# M2354 register map
File version: 1.0
Registers are 32-bit, read-write, reset 0x0 unless marked. A register's access mark holds for its fields unless they carry their own. Offsets are from the block's base; [hi:lo] are bit positions.

## TMR5 — TIMER Register Map
Base 0x40052100
Same registers: TMR5_NS 0x50052100
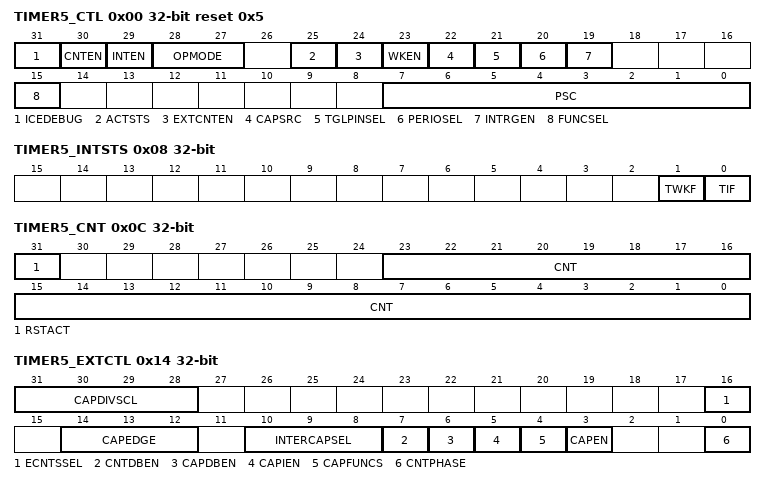
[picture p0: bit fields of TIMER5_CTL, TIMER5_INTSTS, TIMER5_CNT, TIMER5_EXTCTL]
0x00 TIMER5_CTL reset 0x5 — Timer5 Control Register
  [31] ICEDEBUG — ICE Debug Mode Acknowledge Disable Bit (Write Protect). TIMER counter will keep going no matter CPU is held by ICE or not. Note: This bit is write protected. Refer to the SYS_REGLCTL register.
    0=ICE debug mode acknowledgement effects TIMER counting; 1=ICE debug mode acknowledgement Disabled
  [30] CNTEN — Timer Counting Enable Bit. Note 3: Set enable/disable this bit needs 2 * TMR_CLK period to become active, user can read ACTSTS (TIMERx_CTL[25]) to check enable/disable command is completed or not.
    0=Stops/Suspends counting; 1=Starts counting
  [29] INTEN — Timer Interrupt Enable Bit. Note: If this bit is enabled, when the timer time-out interrupt flag TIF is set to 1, the timer interrupt signal is generated and inform to CPU.
    0=Timer time-out interrupt Disabled; 1=Timer time-out interrupt Enabled
  [28:27] OPMODE — Timer Counting Mode Select
    0=The timer controller is operated in One-shot mode; 1=The timer controller is operated in Periodic mode; 2=The timer controller is operated in Toggle-output mode; 3=The timer controller is operated in Continuous Counting mode
  [25] ACTSTS ro — Timer Active Status Bit (Read Only). This bit indicates the 24-bit up counter status. Note: This bit may active when CNT 0 transition to CNT 1.
    0=24-bit up counter is not active; 1=24-bit up counter is active
  [24] EXTCNTEN — Event Counter Mode Enable Bit. This bit is for external counting pin function enabled. Note: When timer is used as an event counter, this bit should be set to 1 and select PCLK as timer clock source.
    0=Event counter mode Disabled; 1=Event counter mode Enabled
  [23] WKEN — Wake-up Function Enable Bit. If this bit is set to 1, while timer interrupt flag TIF (TIMERx_INTSTS[0]) is 1 and INTEN (TIMERx_CTL[29]) is enabled, the timer interrupt signal will generate a wake-up trigger event to CPU.
    0=Wake-up function Disabled if timer interrupt signal generated; 1=Wake-up function Enabled if timer interrupt signal generated
  [22] CAPSRC — Capture Pin Source Selection. Note 2: MIRC clock source is only available in Timer4 ~ Timer5.
    0=Capture Function source is from TMx_EXT (x= 0~5) pin; 1=Capture Function source is from internal ACMP output signal, internal clock source (HIRC, LIRC, MIRC) or external clock (HXT, LXT)
  [21] TGLPINSEL — Toggle-output Pin Select
    0=Toggle mode output to TMx (Timer Event Counter Pin); 1=Toggle mode output to TMx_EXT (Timer External Capture Pin)
  [20] PERIOSEL — Periodic Mode Behavior Selection Enable Bit. If updated CMPDAT value CNT, CNT will be reset to default value.
    0=The behavior selection in periodic mode is Disabled; 1=The behavior selection in periodic mode is Enabled
  [19] INTRGEN — Inter-timer Trigger Mode Enable Bit. Setting this bit will enable the inter-timer trigger capture function. The Timer0/2/4 will be in event counter mode and counting with external clock source or event.Also, Timer1/3/5 will be in trigger-counting mode of capture function. Note: For Timer1/3/5, this bit is ignored and the read back value is always 0.
    0=Inter-Timer Trigger Capture mode Disabled; 1=Inter-Timer Trigger Capture mode Enabled
  [15] FUNCSEL — Function Selection. This bit sets the operation mode of Timer4 and Timer5 to PWM function.
    0=Timer controller is used as timer function; 1=Timer controller is used as PWM function
  [7:0] PSC — Prescale Counter. Note: Update prescale counter value will reset internal 8-bit prescale counter and 24-bit up counter value.
0x04 TIMER5_CMP — Timer5 Comparator Register
  [23:0] CMPDAT — Timer Comparator Value. CMPDAT is a 24-bit compared value register. When the internal 24-bit up counter value is equal to CMPDAT value, the TIF (TIMERx_INTSTS[0] Timer Interrupt Flag) will be set to 1. Note 1: Never write 0x0 or 0x1 in CMPDAT field, or the core will run into unknown state. Note 2: When timer is operating in continuous counting mode, the 24-bit up counter will keep counting continuously even if user writes a new value into CMPDAT field. But if timer is operating at other modes, the 24-bit up counter will restart counting from 0 and use the newest CMPDAT value to be the timer compared value while user writes a new value into the CMPDAT field.
0x08 TIMER5_INTSTS — Timer5 Interrupt Status Register
  [1] TWKF — Timer Wake-up Flag. This bit indicates the interrupt wake-up flag status of timer. Note: This bit is cleared by writing 1 to it.
    0=Timer does not cause CPU wake-up; 1=CPU wake-up from Idle or Power-down mode if timer time-out interrupt signal generated
  [0] TIF — Timer Interrupt Flag. This bit indicates the interrupt flag status of Timer while 24-bit timer up counter CNT (TIMERx_CNT[23:0]) value reaches to CMPDAT (TIMERx_CMP[23:0]) value. Note: This bit is cleared by writing 1 to it.
    0=No effect; 1=CNT value matches the CMPDAT value
0x0C TIMER5_CNT — Timer5 Data Register
  [31] RSTACT ro — Timer Data Register Reset Active (Read Only). This bit indicates if the counter reset operation active. When user writes this CNT register, timer starts to reset its internal 24-bit timer up-counter to 0 and reload 8-bit pre-scale counter. At the same time, timer set this flag to 1 to indicate the counter reset operation is in progress. Once the counter reset operation done, timer clear this bit to 0 automatically.
    0=Reset operation is done; 1=Reset operation triggered by writing TIMERx_CNT is in progress
  [23:0] CNT — Timer Data Register. Read operation. Read this register to get CNT value. For example: If EXTCNTEN (TIMERx_CTL[24]) is 0, user can read CNT value for getting current 24-bit counter value. If EXTCNTEN (TIMERx_CTL[24]) is 1, user can read CNT value for getting current 24-bit event input counter value. Write operation. Writing any value to this register will reset current CNT value to 0 and reload internal 8-bit prescale counter.
0x10 TIMER5_CAP ro — Timer5 Capture Data Register
  [23:0] CAPDAT — Timer Capture Data Register. When CAPEN (TIMERx_EXTCTL[3]) bit is set, the transition on the capture source matches the CAPEDGE (TIMERx_EXTCTL[14:12]) setting, CAPIF (TIMERx_EINTSTS[0]) will be set to 1 and the current timer counter value CNT (TIMERx_CNT[23:0]) will be auto-loaded into this CAPDAT field.
0x14 TIMER5_EXTCTL — Timer5 External Control Register
  [31:28] CAPDIVSCL — Timer Capture Source Divider Scale. These bits indicate the divide scale for capture source divider. Note: Sets INTERCAPSEL (TIMERx_EXTCTL[10:8]) and CAPSRC (TIMERx_CTL[22]) to select capture source.
    0=Capture source/1; 1=Capture source/2; 2=Capture source/4; 3=Capture source/8; 4=Capture source/16; 5=Capture source/32; 6=Capture source/64; 7=Capture source/128; 8=Capture source/256
  [16] ECNTSSEL — Event Counter Source Selection to Trigger Event Counter Function
    0=Event Counter input source is from TMx (x= 0~5) pin; 1=Event Counter input source is from USB internal SOF output signal
  [14:12] CAPEDGE — Timer Capture Edge Detect. When the first capture event is generated, the CNT (TIMERx_CNT[23:0]) will be reset to 0 and first CAPDAT (TIMERx_CAP[23:0]) should be to 0. Note: Set CAPSRC (TIMERx_CTL[22]) and INTERCAPSEL (TIMERx_EXTCTL[10:8]) to select capture source.
    0=Capture event occurred when detect falling edge transfer on capture source; 1=Capture event occurred when detect rising edge transfer on capture source; 2=Capture event occurred when detect both falling and rising edge transfer on capture source, and the first capture event occurred at falling edge transfer; 3=Capture event occurred when detect both rising and falling edge transfer on capture source, and the first capture event occurred at rising edge transfer; 6=First capture event occurred at falling edge, follows capture events are at rising edge transfer on capture source; 7=First capture event occurred at rising edge, follows capture events are at falling edge transfer on capture source
  [10:8] INTERCAPSEL — Internal Capture Source Select. Note: These bits only available when CAPSRC (TIMERx_CTL[22]) is 1.
    0=Capture Function source is from internal ACMP0 output signal; 1=Capture Function source is from internal ACMP1 output signal; 2=Capture Function source is from HXT; 3=Capture Function source is from LXT; 4=Capture Function source is from HIRC; 5=Capture Function source is from LIRC; 6=Capture Function source is from MIRC, only available in Timer4 and Timer5
  [7] CNTDBEN — Timer External Counter Pin De-bounce Enable Bit. Note: If this bit is enabled, the edge detection of TMx pin is detected with de-bounce circuit.
    0=TMx (x= 0~5) pin de-bounce Disabled; 1=TMx (x= 0~5) pin de-bounce Enabled
  [6] CAPDBEN — Timer Capture De-bounce Enable Bit. Note: If this bit is enabled, the edge detection of TMx_EXT pin or ACMP output is detected with de-bounce circuit.
    0=TMx_EXT (x= 0~5) pin de-bounce or ACMP output de-bounce Disabled; 1=TMx_EXT (x= 0~5) pin de-bounce or ACMP output de-bounce Enabled
  [5] CAPIEN — Timer Capture Interrupt Enable Bit
    0=TMx_EXT (x= 0~5) pin, ACMP, internal clock, or external clock detection Interrupt Disabled; 1=TMx_EXT (x= 0~5) pin, ACMP, internal clock, or external clock detection Interrupt Enabled
  [4] CAPFUNCS — Capture Function Selection. Note 1: When CAPFUNCS is 0 and CAPIF becomes 1, the current 24-bit timer counter value (CNT value) will be saved to CAPDAT field. Note 2: When CAPFUNCS is 1 and CAPIF becomes 1, the current 24-bit timer counter value (CNT value) will be saved to CAPDAT field then CNT value will be reset immediately.
    0=Capture Mode Enabled; 1=Reset Mode Enabled
  [3] CAPEN — Timer Capture Function Enable Bit. This bit enables the capture input function.
    0=Timer capture function Disabled; 1=Timer capture function Enabled
  [0] CNTPHASE — Timer External Count Phase
    0=A falling edge of external counting pin will be counted; 1=A rising edge of external counting pin will be counted
0x18 TIMER5_EINTSTS — Timer5 External Interrupt Status Register
  [0] CAPIF — Timer Capture Interrupt Flag. This bit indicates the timer capture interrupt flag status. Note 1: This bit is cleared by writing 1 to it. Note 2: When the CAPEN (TIMERx_EXTCTL[3]) bit is set, the transition on the capture source matches the CAPEDGE (TIMERx_EXTCTL[14:12]) setting, this bit will be set to 1 by hardware. Note 3: There is a new incoming capture event detected before CPU clearing the CAPIF status. If the above condition occurred, the timer will keep register TIMERx_CAP unchanged and drop the new capture value.
    0=TMx_EXT (x= 0~5) pin, ACMP, internal clock, or external clock capture interrupt did not occur; 1=TMx_EXT (x= 0~5) pin, ACMP, internal clock, or external clock capture interrupt occurred
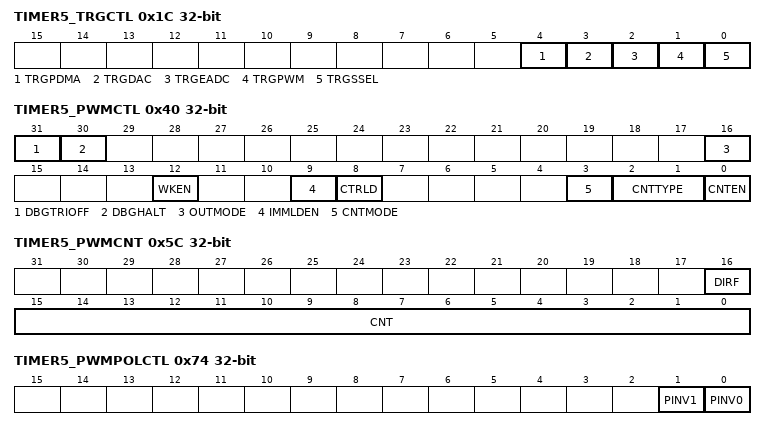
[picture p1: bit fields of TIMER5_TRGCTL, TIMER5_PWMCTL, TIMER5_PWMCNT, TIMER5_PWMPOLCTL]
0x1C TIMER5_TRGCTL — Timer5 Trigger Control Register
  [4] TRGPDMA — Trigger PDMA Enable Bit. If this bit is set to 1, each timer time-out event or capture event can be triggered PDMA transfer.
    0=Timer interrupt trigger PDMA Disabled; 1=Timer interrupt trigger PDMA Enabled
  [3] TRGDAC — Trigger DAC Enable Bit. If this bit is set to 1, each timer time-out event or capture event can be triggered DAC.
    0=Timer interrupt trigger DAC Disabled; 1=Timer interrupt trigger DAC Enabled
  [2] TRGEADC — Trigger EADC Enable Bit. If this bit is set to 1, each timer time-out event or capture event can be triggered EADC conversion.
    0=Timer interrupt trigger EADC Disabled; 1=Timer interrupt trigger EADC Enabled
  [1] TRGPWM — Trigger EPWM and BPWM Enable Bit. If this bit is set to 1, each timer time-out event or capture event can be as EPWM and BPWM counter clock source.
    0=Timer interrupt trigger EPWM and BPWM Disabled; 1=Timer interrupt trigger EPWM and BPWM Enabled
  [0] TRGSSEL — Trigger Source Select Bit. This bit is used to select internal trigger source is form timer time-out interrupt signal or capture interrupt signal.
    0=Time-out interrupt signal is used to internal trigger EPWM/BPWM, PDMA, DAC, and EADC; 1=Capture interrupt signal is used to internal trigger EPWM/BPWM, PDMA, DAC, and EADC
0x40 TIMER5_PWMCTL — Timer5 PWM Control Register
  [31] DBGTRIOFF — ICE Debug Mode Acknowledge Disable Bit (Write Protect). PWM output pin will keep output no matter ICE debug mode acknowledged or not. Note: This bit is write protected. Refer toSYS_REGLCTL register.
    0=ICE debug mode acknowledgement effects PWM output; 1=ICE debug mode acknowledgement disabled
  [30] DBGHALT — ICE Debug Mode Counter Halt (Write Protect). If debug mode counter halt is enabled, PWM counter will keep current value until exit ICE debug mode. Note: This bit is write protected. Refer toSYS_REGLCTL register.
    0=ICE debug mode counter halt disable; 1=ICE debug mode counter halt enable
  [16] OUTMODE — PWM Output Mode. This bit controls the output mode of corresponding PWM channel. Note: This bit is not available in Timer4 and Timer5.
    0=PWM independent mode; 1=PWM complementary mode
  [12] WKEN — PWM Wake-up Enable Bit. If this bit is set to 1, the Timer4 and Timer5 PWM interrupt event will generate a wake-up trigger event to CPU. Note: This bit is only available in Timer4 and Timer5.
    0=PWM interrupt wake-up Disabled; 1=PWM interrupt wake-up Enabled
  [9] IMMLDEN — Immediately Load Enable Bit. Note 1: This bit is not available in Timer4 and Timer5. Note 2: If IMMLDEN is enabled, CTRLD will be invalid.
    0=PERIOD will load to PBUF when current PWM period is completed no matter CTRLD is enabled/disabled. If CTRLD is disabled, CMP will load to CMPBUF when current PWM period is completed; if CTRLD is enabled in up-down count type, CMP will load to CMPBUF at the center point of current period; 1=PERIOD/CMP will load to PBUF/CMPBUF immediately when user update PERIOD/CMP
  [8] CTRLD — Center Re-load. In up-down count type, PERIOD will load to PBUF when current PWM period is completed always and CMP will load to CMPBUF at the center point of current period. Note: This bit is not available in Timer4 and Timer5.
  [3] CNTMODE — PWM Counter Mode
    0=Auto-reload mode; 1=One-shot mode
  [2:1] CNTTYPE — PWM Counter Behavior Type. These bits are used to set the count type of Timer0 ~ Timer3. The count type of Timer4 and Timer5 is fixed as the up count type. Note: These bits are not available in Timer4 and Timer5.
    0=Up count type; 1=Down count type; 2=Up-down count type
  [0] CNTEN — PWM Counter Enable Bit
    0=PWM counter and clock prescale Stop Running; 1=PWM counter and clock prescale Start Running
0x48 TIMER5_PWMCLKPSC — Timer5 PWM Counter Clock Pre-scale Register
  [11:0] CLKPSC — PWM Counter Clock Pre-scale. The active clock of PWM counter is decided by counter clock prescale and divided by (CLKPSC + 1). If CLKPSC is 0, then there is no scaling in PWM counter clock source. Note: The valid value is 12-bit TIMERx_PWMCLKPSC[11:0] in Timer0 ~ Timer3, and 8-bit TIMERx_PWMCLKPSC[7:0] in Timer4 and Timer5.
0x4C TIMER5_PWMCNTCLR — Timer5 PWM Clear Counter Register
  [0] CNTCLR — Clear PWM Counter Control Bit. It is automatically cleared by hardware.
    0=No effect; 1=In Timer0 ~ Timer3, clears 16-bit PWM counter to 0x10000 in up and up-down count type and reset counter value to PERIOD in down count type. In Timer4 and Timer5, clears 16-bit PWM counter to 0x0 in up count type
0x50 TIMER5_PWMPERIOD
  [15:0] PERIOD — PWM Period Register. In up count type: PWM counter counts from 0 to PERIOD, and restarts from 0. In down count type: PWM counter counts from PERIOD to 0, and restarts from PERIOD. In up-down count type: PWM counter counts from 0 to PERIOD, then decrements to 0 and repeats again. In up and down count type: Note 1: The count type of Timer4 and Timer5 is fixed as up count type. Note 2: User should take care DIRF (TIMERx_PWMCNT[16]) bit in up/down/up-down count type to monitor current counter direction in each count type in Timer0 ~ Timer3.
0x54 TIMER5_PWMCMPDAT — Timer5 PWM Comparator Register
  [15:0] CMP — PWM Comparator Register. PWM CMP is used to compare with PWM CNT to generate PWM output waveform, interrupt events and trigger EADC and PDMA to start conversion.
0x5C TIMER5_PWMCNT ro — Timer5 PWM Counter Register
  [16] DIRF — PWM Counter Direction Indicator Flag (Read Only). Note 1: This indicator flag is used for Timer0 ~ Timer3 only. Note 2: Since the count type of Timer4 ~ Timer5 is fixed as up count, this bit is fixed 0 in Timer4 and Timer5.
    0=Counter is active in down count; 1=Counter is active up count
  [15:0] CNT — PWM Counter Value Register (Read Only). User can monitor CNT to know the current counter value in 16-bit period counter.
0x74 TIMER5_PWMPOLCTL — Timer5 PWM Pin Output Polar Control Register
  [1] PINV1 — PWMx_CH1 Output Pin Polar Control Bit. The bit is used to control polarity state of PWMx_CH1 output pin. Note: This bit is not available in Timer4 and Timer5.
    0=PWMx_CH1 output pin polar inverse Disabled; 1=PWMx_CH1 output pin polar inverse Enabled
  [0] PINV0 — PWMx_CH0 Output Pin Polar Control Bit. The bit is used to control polarity state of PWMx_CH0 output pin.
    0=PWMx_CH0 output pin polar inverse Disabled; 1=PWMx_CH0 output pin polar inverse Enabled
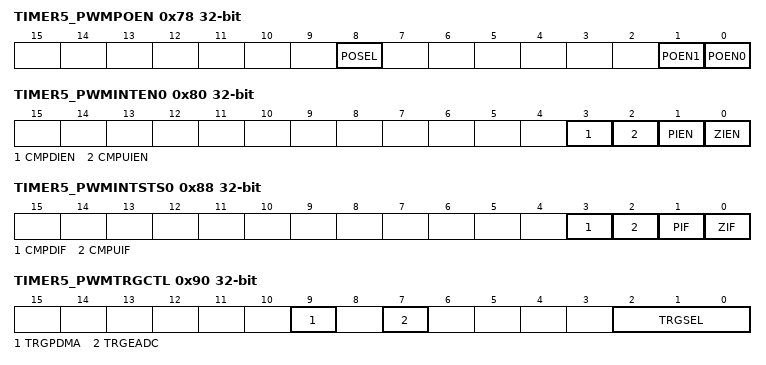
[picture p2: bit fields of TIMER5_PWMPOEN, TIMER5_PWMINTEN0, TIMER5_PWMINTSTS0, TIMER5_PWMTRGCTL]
0x78 TIMER5_PWMPOEN — Timer5 PWM Pin Output Enable Register
  [8] POSEL — PWMx_CH0 Output Pin Select. This bit is used to select the output channel of Timer4 and Timer5 PWM. Note: This bit is only available in Timer4 and Timer5.
    0=PWMx_CH0 pin is TMx; 1=PWMx_CH0 pin is TMx_EXT
  [1] POEN1 — PWMx_CH1 Output Pin Enable Bit. Note: This bit is not available in Timer4 and Timer5.
    0=PWMx_CH1 pin at tri-state mode; 1=PWMx_CH1 pin in output mode
  [0] POEN0 — PWMx_CH0 Output Pin Enable Bit
    0=PWMx_CH0 pin at tri-state mode; 1=PWMx_CH0 pin in output mode
0x80 TIMER5_PWMINTEN0 — Timer5 PWM Interrupt Enable Register 0
  [3] CMPDIEN — PWM Compare Down Count Interrupt Enable Bit. Note: This bit is not available in Timer4 and Timer5
    0=Compare down count interrupt Disabled; 1=Compare down count interrupt Enabled
  [2] CMPUIEN — PWM Compare Up Count Interrupt Enable Bit
    0=Compare up count interrupt Disabled; 1=Compare up count interrupt Enabled
  [1] PIEN — PWM Period Point Interrupt Enable Bit. Note: In up-down count type, period point means the center point of current PWM period.
    0=Period point interrupt Disabled; 1=Period point interrupt Enabled
  [0] ZIEN — PWM Zero Point Interrupt Enable Bit. Note: This bit is not available in Timer4 and Timer5
    0=Zero point interrupt Disabled; 1=Zero point interrupt Enabled
0x88 TIMER5_PWMINTSTS0 — Timer5 PWM Interrupt Status Register 0
  [3] CMPDIF — PWM Compare Down Count Interrupt Flag. This bit is set by hardware when TIMERx_PWM counter in down count direction and reaches CMP. Note 1: This bit is not available in Timer4 and Timer5. Note 2: If CMP equal to PERIOD, there is no CMPDIF flag in down count type. Note 3: This bit is cleared by writing 1 to it.
  [2] CMPUIF — PWM Compare Up Count Interrupt Flag. This bit is set by hardware when TIMERx_PWM counter in up count direction and reaches CMP. Note 1: If CMP equal to PERIOD, there is no CMPUIF flag in up count type and up-down count type. Note 2: This bit is cleared by writing 1 to it.
  [1] PIF — PWM Period Point Interrupt Flag. This bit is set by hardware when TIMERx_PWM counter reaches PERIOD. Note 1: In up-down count type, PIF flag means the center point flag of current PWM period. Note 2: This bit is cleared by writing 1 to it.
  [0] ZIF — PWM Zero Point Interrupt Flag. This bit is set by hardware when TIMERx_PWM counter reaches 0. Note 1: This bit is not available in Timer4 and Timer5. Note 2: This bit is cleared by writing 1 to it.
0x90 TIMER5_PWMTRGCTL — Timer5 PWM Trigger Control Register
  [9] TRGPDMA — PWM Counter Event Trigger PDMA Conversion Enable Bit. Note 1: This bit is only available in Timer4 and Timer5. Note 2: Set TRGSEL (TIMERx_PWMTRGCTL[2:0]) to select PWM trigger conversion source.
    0=PWM counter event trigger PDMA Disabled; 1=PWM counter event trigger PDMA Enabled
  [7] TRGEADC — PWM Counter Event Trigger EADC Conversion Enable Bit. Note: Set TRGSEL (TIMERx_PWMTRGCTL[2:0]) to select PWM trigger conversion source.
    0=PWM counter event trigger EADC conversion Disabled; 1=PWM counter event trigger EADC conversion Enabled
  [2:0] TRGSEL — PWM Counter Event Source Select to Trigger Conversion. In Timer0 ~ Timer3,
    0=Trigger conversion at zero point (ZIF); 1=Trigger conversion at period point (PIF); 2=Trigger conversion at zero or period point (ZIF or PIF); 3=Trigger conversion at compare up count point (CMPUIF); 4=Trigger conversion at compare down count point (CMPDIF); 5=Trigger conversion at period or compare up count point (PIF or CMPUIF)
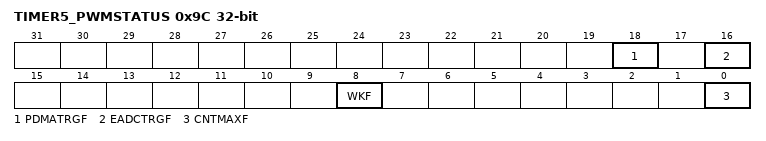
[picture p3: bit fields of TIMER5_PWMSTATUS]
0x9C TIMER5_PWMSTATUS
  [18] PDMATRGF — Trigger PDMA Start Conversion Flag. Note 1: This bit is only available in Timer4 and Timer5. Note 2: This bit is cleared by writing 1 to it.
    0=PWM counter event trigger PDMA start conversion did not occur; 1=PWM counter event trigger PDMA start conversion occurred
  [16] EADCTRGF — Trigger EADC Start Conversion Flag. Note: This bit is cleared by writing 1 to it.
    0=PWM counter event trigger EADC start conversion did not occur; 1=PWM counter event trigger EADC start conversion occurred
  [8] WKF — PWM Wake-up Flag. Note 1: This bit is only available in Timer4 and Timer5. Note 2: This bit is cleared by writing 1 to it.
    0=PWM interrupt wake-up did not occur; 1=PWM interrupt wake-up occurred
  [0] CNTMAXF — PWM Counter Equal to 0xFFFF Flag. Note: This bit is cleared by writing 1 to it.
    0=The PWM counter value never reached its maximum value 0xFFFF; 1=The PWM counter value has reached its maximum value
0xA0 TIMER5_PWMPBUF ro — Timer5 PWM Period Buffer Register
  [15:0] PBUF — PWM Period Buffer Register (Read Only). Used as PERIOD active register.
0xA4 TIMER5_PWMCMPBUF ro — Timer5 PWM Comparator Buffer Register
  [15:0] CMPBUF — PWM Comparator Buffer Register (Read Only). Used as CMP active register.
